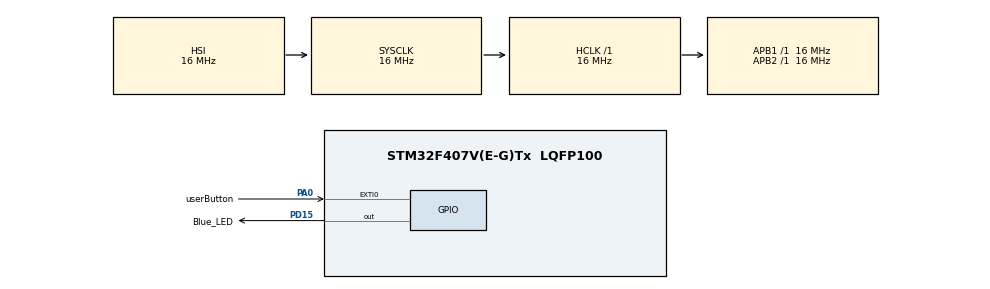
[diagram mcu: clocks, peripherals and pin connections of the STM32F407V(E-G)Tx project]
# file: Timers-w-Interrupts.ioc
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Mcu.Family=STM32F4
Mcu.Name=STM32F407V(E-G)Tx
Mcu.Package=LQFP100
NVIC.EXTI0_IRQn=true\:0\:0\:false\:true\:true\:1\:true\:true\:true
NVIC.PriorityGroup=NVIC_PRIORITYGROUP_4
NVIC.TIM8_UP_TIM13_IRQn=true\:0\:0\:false\:false\:true\:true\:true\:true
PA0-WKUP.GPIO_Label=userButton
PA0-WKUP.GPIO_ModeDefaultEXTI=GPIO_MODE_IT_RISING_FALLING
PA0-WKUP.Signal=GPXTI0
PD15.GPIO_Label=Blue_LED
PD15.GPIO_PuPd=GPIO_PULLDOWN
PD15.Signal=GPIO_Output
PH0-OSC_IN.Mode=HSE-External-Oscillator
PH0-OSC_IN.Signal=RCC_OSC_IN
PH1-OSC_OUT.Mode=HSE-External-Oscillator
PH1-OSC_OUT.Signal=RCC_OSC_OUT
ProjectManager.HeapSize=0x200
ProjectManager.StackSize=0x400
ProjectManager.TargetToolchain=STM32CubeIDE
RCC.AHBFreq_Value=16000000
RCC.APB1Freq_Value=16000000
RCC.APB1TimFreq_Value=16000000
RCC.APB2Freq_Value=16000000
RCC.APB2TimFreq_Value=16000000
RCC.CortexFreq_Value=16000000
RCC.HCLKFreq_Value=16000000
RCC.HSE_VALUE=25000000
RCC.HSI_VALUE=16000000
RCC.LSE_VALUE=32768
RCC.SYSCLKFreq_VALUE=16000000
RCC.VCOOutputFreq_Value=192000000
TIM13.AutoReloadPreload=TIM_AUTORELOAD_PRELOAD_ENABLE
TIM13.Period=1599
TIM13.Prescaler=9999
VP_TIM13_VS_ClockSourceINT.Mode=Enable_Timer
board=custom

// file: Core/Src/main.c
/* USER CODE BEGIN Header */
/**
  ******************************************************************************
  * @file           : main.c
  * @brief          : Main program body
  ******************************************************************************
  * @attention
  *
  * Copyright (c) 2024 STMicroelectronics.
  * All rights reserved.
  *
  * This software is licensed under terms that can be found in the LICENSE file
  * in the root directory of this software component.
  * If no LICENSE file comes with this software, it is provided AS-IS.
  *
  ******************************************************************************
  */
/* USER CODE END Header */
#include "main.h"

TIM_HandleTypeDef htim13;

/* USER CODE BEGIN PV */
int LEDstatus = 0;
int LEDchangeState = 0;
/* USER CODE END PV */

void SystemClock_Config(void);
static void MX_GPIO_Init(void);
static void MX_TIM13_Init(void);
static void MX_NVIC_Init(void);
/* USER CODE BEGIN PFP */

//void HAL_GPIO_EXTI_Callback(uint16_t GPIO_Pin);
//void HAL_TIM_PeriodElapsedCallback(TIM_HandleTypeDef *htim);

/* USER CODE END PFP */

int main(void)
{

  /* MCU Configuration--------------------------------------------------------*/

  /* Reset of all peripherals, Initializes the Flash interface and the Systick. */
  HAL_Init();

  /* Configure the system clock */
  SystemClock_Config();

  /* Initialize all configured peripherals */
  MX_GPIO_Init();
  MX_TIM13_Init();

  /* Initialize interrupts */
  MX_NVIC_Init();

  /* Infinite loop */
  while (1)
  {

  }
}

void SystemClock_Config(void)
{
  RCC_OscInitTypeDef RCC_OscInitStruct = {0};
  RCC_ClkInitTypeDef RCC_ClkInitStruct = {0};

  /** Configure the main internal regulator output voltage
  */
  __HAL_RCC_PWR_CLK_ENABLE();
  __HAL_PWR_VOLTAGESCALING_CONFIG(PWR_REGULATOR_VOLTAGE_SCALE1);

  /** Initializes the RCC Oscillators according to the specified parameters
  * in the RCC_OscInitTypeDef structure.
  */
  RCC_OscInitStruct.OscillatorType = RCC_OSCILLATORTYPE_HSI;
  RCC_OscInitStruct.HSIState = RCC_HSI_ON;
  RCC_OscInitStruct.HSICalibrationValue = RCC_HSICALIBRATION_DEFAULT;
  RCC_OscInitStruct.PLL.PLLState = RCC_PLL_NONE;
  if (HAL_RCC_OscConfig(&RCC_OscInitStruct) != HAL_OK)
  {
    Error_Handler();
  }

  /** Initializes the CPU, AHB and APB buses clocks
  */
  RCC_ClkInitStruct.ClockType = RCC_CLOCKTYPE_HCLK|RCC_CLOCKTYPE_SYSCLK
                              |RCC_CLOCKTYPE_PCLK1|RCC_CLOCKTYPE_PCLK2;
  RCC_ClkInitStruct.SYSCLKSource = RCC_SYSCLKSOURCE_HSI;
  RCC_ClkInitStruct.AHBCLKDivider = RCC_SYSCLK_DIV1;
  RCC_ClkInitStruct.APB1CLKDivider = RCC_HCLK_DIV1;
  RCC_ClkInitStruct.APB2CLKDivider = RCC_HCLK_DIV1;

  if (HAL_RCC_ClockConfig(&RCC_ClkInitStruct, FLASH_LATENCY_0) != HAL_OK)
  {
    Error_Handler();
  }
}

/**
  * @brief NVIC Configuration.
  * @retval None
  */
static void MX_NVIC_Init(void)
{
  /* EXTI0_IRQn interrupt configuration */
  HAL_NVIC_SetPriority(EXTI0_IRQn, 0, 0);
  HAL_NVIC_EnableIRQ(EXTI0_IRQn);
}

static void MX_TIM13_Init(void)
{

  htim13.Instance = TIM13;
  htim13.Init.Prescaler = 9999;
  htim13.Init.CounterMode = TIM_COUNTERMODE_UP;
  htim13.Init.Period = 1599;
  htim13.Init.ClockDivision = TIM_CLOCKDIVISION_DIV1;
  htim13.Init.AutoReloadPreload = TIM_AUTORELOAD_PRELOAD_ENABLE;
  if (HAL_TIM_Base_Init(&htim13) != HAL_OK)
  {
    Error_Handler();
  }
  /* USER CODE BEGIN TIM13_Init 2 */

  // manual set auto-reload value (ie. period) before starting timer for first time
  TIM13->ARR = 1599;
  // clear 'update interrupt' flag which is automatically set when timer initialized
  TIM13->SR &= ~(TIM_SR_UIF);

  /* USER CODE END TIM13_Init 2 */

}

static void MX_GPIO_Init(void)
{
  GPIO_InitTypeDef GPIO_InitStruct = {0};

  /* GPIO Ports Clock Enable */
  __HAL_RCC_GPIOH_CLK_ENABLE();
  __HAL_RCC_GPIOA_CLK_ENABLE();
  __HAL_RCC_GPIOD_CLK_ENABLE();

  /*Configure GPIO pin Output Level */
  HAL_GPIO_WritePin(Blue_LED_GPIO_Port, Blue_LED_Pin, GPIO_PIN_RESET);

  /*Configure GPIO pin : userButton_Pin */
  GPIO_InitStruct.Pin = userButton_Pin;
  GPIO_InitStruct.Mode = GPIO_MODE_IT_RISING_FALLING;
  GPIO_InitStruct.Pull = GPIO_NOPULL;
  HAL_GPIO_Init(userButton_GPIO_Port, &GPIO_InitStruct);

  /*Configure GPIO pin : Blue_LED_Pin */
  GPIO_InitStruct.Pin = Blue_LED_Pin;
  GPIO_InitStruct.Mode = GPIO_MODE_OUTPUT_PP;
  GPIO_InitStruct.Pull = GPIO_PULLDOWN;
  GPIO_InitStruct.Speed = GPIO_SPEED_FREQ_LOW;
  HAL_GPIO_Init(Blue_LED_GPIO_Port, &GPIO_InitStruct);

}

/* USER CODE BEGIN 4 */

// HAL_GPIO_EXTI_Callback handles interrupts caused by GPIO pins
void HAL_GPIO_EXTI_Callback(uint16_t GPIO_Pin){

	// check that interrupt was generated by userButton pin
	if(GPIO_Pin == userButton_Pin){

		// if the pin is HI, the button was pressed
		if(HAL_GPIO_ReadPin(userButton_GPIO_Port, userButton_Pin)){
			// start timer in interrupt mode
			HAL_TIM_Base_Start_IT(&htim13);

		// if the pin is LO, the button was released
		}else if(!(HAL_GPIO_ReadPin(userButton_GPIO_Port, userButton_Pin))){

			// stop timer
			HAL_TIM_Base_Stop_IT(&htim13);

			// reset timer count register (there's no HAL function for this)
			TIM13->CNT = 0;

			// turn off the LED if it's on
			HAL_GPIO_WritePin(Blue_LED_GPIO_Port, Blue_LED_Pin, GPIO_PIN_RESET);
		}
	}
}

// HAL_TIM_PeriodElapsedCallback is called when a timer counter fills up
void HAL_TIM_PeriodElapsedCallback(TIM_HandleTypeDef *htim){

	// check that timer 13 created the interrupt
	if (htim == &htim13){

		// turn on the LED (since this callback was called, we know 100ms have passed)
		HAL_GPIO_WritePin(Blue_LED_GPIO_Port, Blue_LED_Pin, GPIO_PIN_SET);
	}
}

/* USER CODE END 4 */

void Error_Handler(void)
{
  __disable_irq();
  while (1)
  {
  }
}
